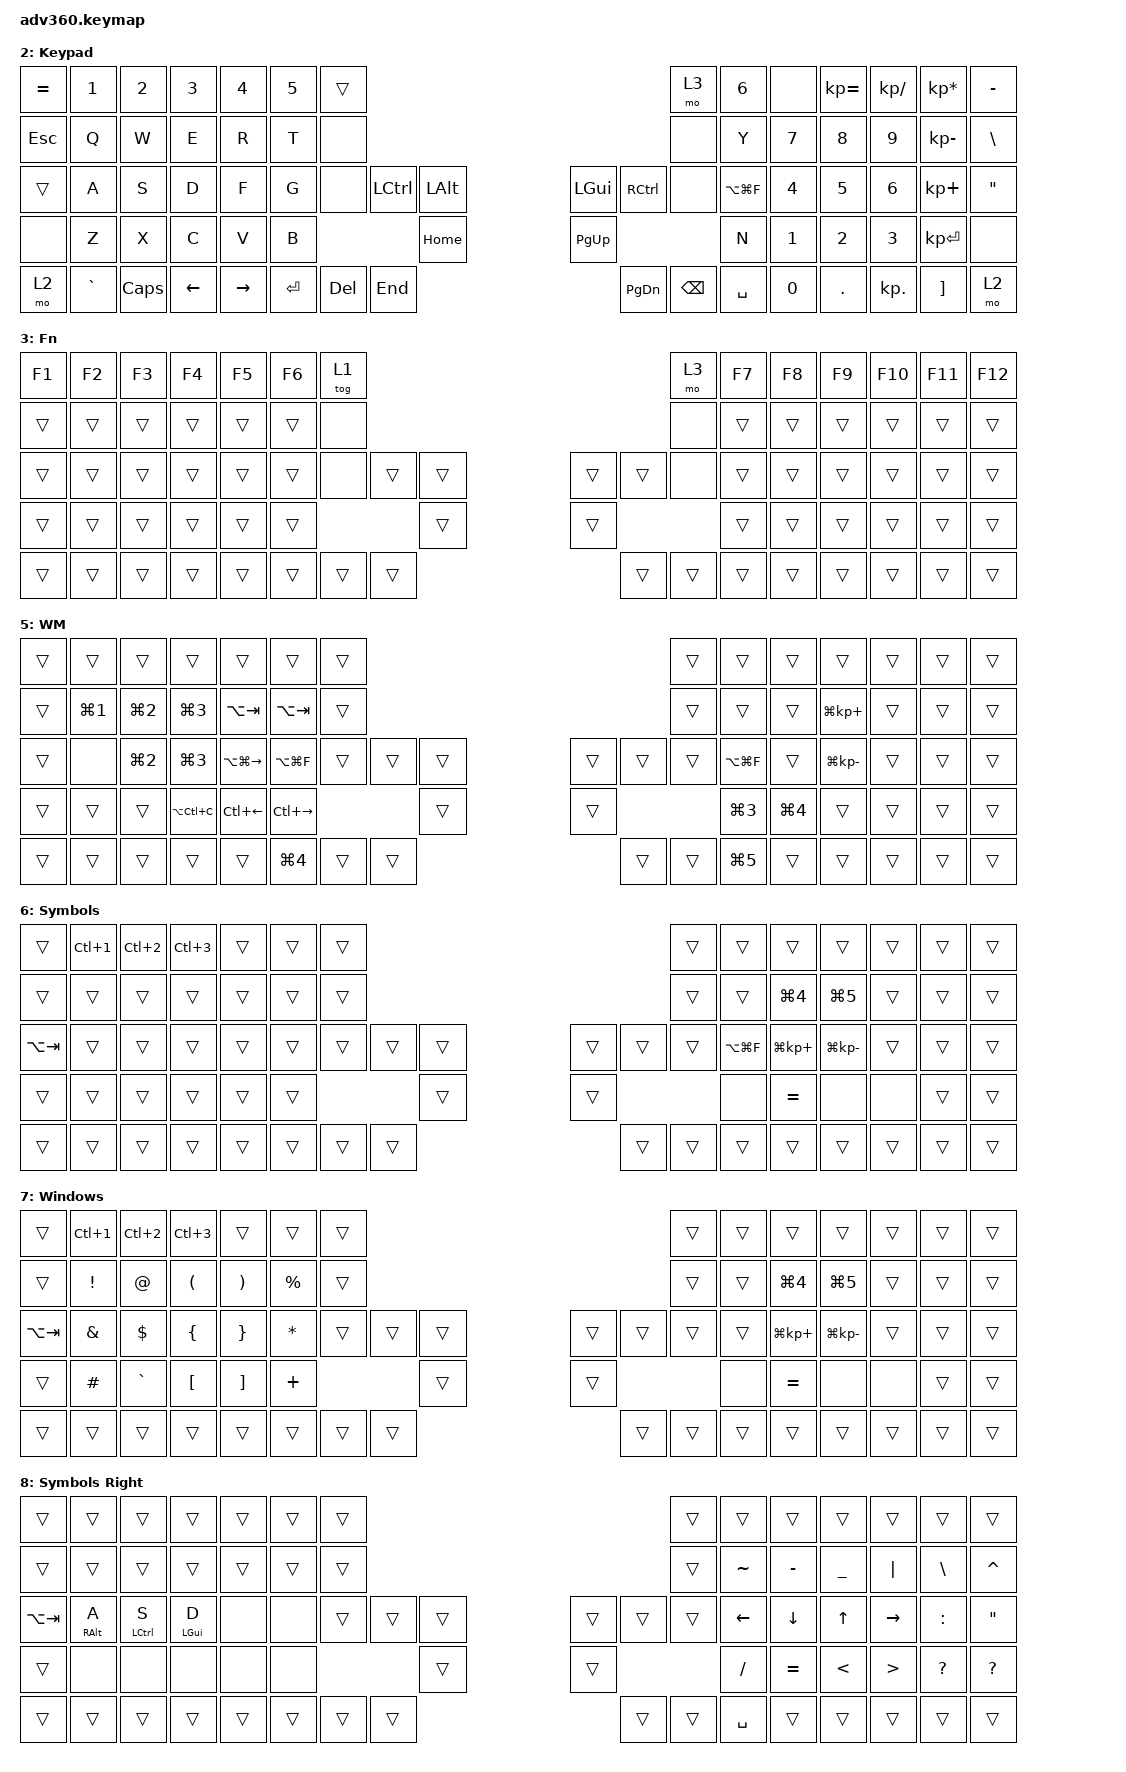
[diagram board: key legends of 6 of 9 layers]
#include <behaviors.dtsi>
#include <dt-bindings/zmk/keys.h>
#include <dt-bindings/zmk/bt.h>
#include <dt-bindings/zmk/rgb.h>
#include <dt-bindings/zmk/stp.h>
#include <dt-bindings/zmk/backlight.h>
#include <dt-bindings/zmk/pointing.h>

&lt {
    tapping-term-ms = <150>;
    flavor = "tap-preferred";
    quick_tap_ms = <80>;
};

&sl {
    release-after-ms = <2000>;
};

#define ZOOM_IN &kp LG(KP_PLUS)
#define ZOOM_OUT &kp LG(KP_MINUS)


/ {
    combos {
        compatible = "zmk,combos";
        combo_esc {
            timeout-ms = <50>;
            key-positions = <31 32>;
            bindings = <&kp A>;
        };
        combo_sqt {
            timeout-ms = <50>;
            key-positions = <41 42>;
            bindings = <&kp SQT>;
        };
    };

    behaviors {
      #include "macros.dtsi"
      #include "version.dtsi"
      #ifndef VERSION_MACRO
      macro_ver: macro_ver {
        compatible = "zmk,behavior-macro";
        label = "macro_version";
        #binding-cells = <0>;
        bindings = <&kp RET>;
      };
      #endif

      hm: homerow_mods {
          compatible = "zmk,behavior-hold-tap";
          label = "HOMEROW_MODS";
          #binding-cells = <2>;
          tapping-term-ms = <150>;
          quick_tap_ms = <150>;
          flavor = "tap-preferred";
          bindings = <&kp>, <&kp>;
      };

      hh: homerow_hold {
          compatible = "zmk,behavior-hold-tap";
          label = "HOMEROW_HOLD";
          #binding-cells = <2>;
          tapping-term-ms = <120>;
          quick_tap_ms = <120>;
          flavor = "balanced";
          bindings = <&mo>, <&kp>;
      };

      ht: homerow_layer_hold {
          compatible = "zmk,behavior-hold-tap";
          label = "HOMEROW_LAYER_HOLD";
          #binding-cells = <2>;
          tapping-term-ms = <150>;
          quick_tap_ms = <150>;
          flavor = "balanced";
          bindings = <&mo>, <&kp>;
      };

      hl: homerow_low_mods {
          compatible = "zmk,behavior-hold-tap";
          label = "HOMEROW_MODS";
          #binding-cells = <2>;
          tapping-term-ms = <120>;
          quick_tap_ms = <120>;
          flavor = "tap-preferred";
          bindings = <&kp>, <&kp>;
      };

      pinky: pinky_low_mod {
          compatible = "zmk,behavior-hold-tap";
          label = "HOMEROW_MODS";
          #binding-cells = <2>;
          tapping-term-ms = <210>;
          quick_tap_ms = <180>;
          flavor = "tap-preferred";
          bindings = <&kp>, <&kp>;
      };

    };

  keymap {
    compatible = "zmk,keymap";

        default_layer {
            display-name = "Base";
            bindings = <
    &kp ESC   &kp N1       &kp N2       &kp N3      &kp N4   &kp N5        &mo 4                                                                               &mo 4    &kp N6   &kp N7   &kp N8     &kp N9      &kp N0           &kp BACKSPACE
 &kp ESCAPE   &kp Q        &kp W        &kp E       &kp R    &kp T         &kp F1                                                                              &kp F2   &kp Y    &kp U    &kp I      &kp O       &kp P            &kp BACKSPACE
    &lt 2 TAB   &pinky RALT A   &hm LCTRL S  &hm LGUI D  &hh 8 F  &kp G         &kp C_VOL_DN &kp C_PP &kp PSCRN   &kp C_PREV   &kp C_NEXT     &kp C_VOL_UP              &kp H    &kp J  &hl LGUI K &hm LCTRL L &hh 7 SEMICOLON  &kp SQT
 &kp LSHIFT   &mt LSHIFT Z &kp X        &kp C       &lt 2 V    &kp B                                            &mo 4               &kp RS(LA(LG(M)))                            &kp N    &kp M    &kp COMMA   &kp DOT  &mt RIGHT_SHIFT SLASH  &mt RSHIFT SLASH
      &mo 3   &kp GRAVE    &kp CAPS     &none       &none                  &kp ENTER         &kp ESC          &kp RS(LG(SPACE))   &kp DELETE   &kp BACKSPACE  &kp SPACE        &sk RIGHT_CONTROL  &sk RGUI   &kp DOT  &kp SLASH        &tog 1
            >;
        };

        // layer 1 (colemak-dhk)
        layer_Colemak_DH {
            display-name = "Colemak DHK";
            bindings = <
    &kp ESC        &kp N1    &kp N2         &kp N3        &kp N4   &kp N5                 &none                                                                            &none            &kp N6   &kp N7   &kp N8     &kp N9   &kp N0          &kp BACKSPACE
 &kp ESCAPE        &kp Q     &kp W          &kp F         &kp P    &kp B                  &tog 1                                                                           &none            &kp J    &kp L    &kp U      &kp Y    &kp SEMICOLON   &kp BACKSPACE
    &lt 2 TAB      &pinky RALT A     &hm LCTRL R          &hh LGUI S         &hh 8 T  &kp G      &kp C_VOLUME_DOWN  &kp C_PLAY_PAUSE  &kp PRINTSCREEN       &kp C_PREV   &kp C_NEXT           &kp C_VOLUME_UP  &kp M    &ht 7 N    &hl LGUI E      &hm LCTRL I    &hh 6 O         &kp SQT
 &kp LSHIFT &mt LSHIFT Z     &kp X          &kp C         &kp D    &kp V                                                     &mo 3       &kp RS(LA(LG(M)))                                  &kp K    &kp H    &kp COMMA  &kp DOT  &mt RIGHT_SHIFT SLASH  &mt RIGHT_SHIFT SLASH
    &tog 0  &kp GRAVE  &kp CAPS  &sk RIGHT_ALT  &sk LEFT_GUI                 &kp ENTER           &kp ESC   &kp RS(LG(SPACE))          &kp DELETE   &kp BACKSPACE  &kp SPACE                 &sk RIGHT_CONTROL  &sk RGUI   &kp DOT  &kp SLASH        &tog 1
            >;
        };

        // layer 2
        layer_keypad {
            display-name = "Keypad";
            bindings = <
  &kp EQUAL     &kp N1    &kp N2    &kp N3     &kp N4  &kp N5              &trans                                                                 &mo 3  &kp N6         &none  &kp KP_EQUAL  &kp KP_DIVIDE  &kp KP_MULTIPLY          &kp MINUS
 &kp ESCAPE      &kp Q     &kp W     &kp E      &kp R   &kp T               &none                                                                 &none   &kp Y  &kp NUMBER_7  &kp NUMBER_8   &kp NUMBER_9     &kp KP_MINUS           &kp BSLH
     &trans      &kp A     &kp S     &kp D      &kp F   &kp G               &none  &kp LCTRL  &kp LALT                   &kp LGUI  &kp RCTRL      &none   &kp LA(LG(F)) &kp NUMBER_4  &kp NUMBER_5   &kp NUMBER_6      &kp KP_PLUS  &kp DOUBLE_QUOTES
      &none      &kp Z     &kp X     &kp C      &kp V   &kp B                                 &kp HOME                  &kp PG_UP                         &kp N  &kp NUMBER_1  &kp NUMBER_2   &kp NUMBER_3     &kp KP_ENTER              &none
      &mo 2  &kp GRAVE  &kp CAPS  &kp LEFT  &kp RIGHT                    &kp ENTER    &kp DEL   &kp END                  &kp PG_DN  &kp BACKSPACE  &kp SPACE   &kp NUMBER_0       &kp DOT     &kp KP_DOT         &kp RBKT              &mo 2
            >;
        };

        // layer 3
        layer_fn {
            display-name = "Fn";
            bindings = <
 &kp F1  &kp F2  &kp F3  &kp F4  &kp F5  &kp F6            &tog 1                                                   &mo 3  &kp F7  &kp F8  &kp F9  &kp F10  &kp F11  &kp F12
 &trans  &trans  &trans  &trans  &trans  &trans             &none                                                   &none  &trans  &trans  &trans   &trans   &trans   &trans
 &trans  &trans  &trans  &trans  &trans  &trans             &none  &trans  &trans                  &trans  &trans   &none  &trans  &trans  &trans   &trans   &trans   &trans
 &trans  &trans  &trans  &trans  &trans  &trans                            &trans                  &trans                  &trans  &trans  &trans   &trans   &trans   &trans
 &trans  &trans  &trans  &trans  &trans                    &trans  &trans  &trans                  &trans  &trans  &trans          &trans  &trans   &trans   &trans   &trans
            >;
        };

        // layer 4
        layer_mod {
            display-name = "Mod";
            bindings = <
  &none  &bt BT_SEL 0  &bt BT_SEL 1  &bt BT_SEL 2  &bt BT_SEL 3   &bt BT_SEL 4                  &none                                                                 &trans       &none  &none      &none       &none   &none   &none
  &none         &none         &none         &none         &none          &none            &bootloader                                                                 &bootloader  &none  &none      &none       &none   &none   &none
  &none         &none         &none         &none    &bt BT_CLR          &none                  &none  &tog 6  &tog 0    &bt BT_CLR   &none  &rgb_ug RGB_MEFS_CMD 5   &none        &none  &none      &none       &none   &none   &none
  &none         &none         &none         &none         &none  &kp RIGHT_WIN                                  &none    &none                                                     &none  &none      &none       &none   &none   &none
  &none         &none         &none         &none         &none                                 &none   &none   &none    &none       &bl BL_TOG    &rgb_ug RGB_TOG                        &bl BL_INC &bl BL_DEC  &none   &none   &none
            >;
        };

        // layer 5
        layer_WINDOW_M {
            display-name = "WM";
            bindings = <
 &trans  &trans            &trans            &trans             &trans         &trans                  &trans                                                     &trans   &trans        &trans      &trans            &trans  &trans  &trans
 &trans  &kp LG(N1)    &kp LG(N2)        &kp LG(N3)        &kp LA(TAB)    &kp LA(TAB)                  &trans                                                     &trans   &trans        &trans      &kp LG(KP_PLUS)   &trans  &trans  &trans
 &trans  &none         &kp LG(N2)        &kp LG(N3)  &kp LA(LG(RIGHT))  &kp LA(LG(F))                  &trans  &trans  &trans                  &trans  &trans     &trans   &kp LA(LG(F)) &trans      &kp LG(KP_MINUS)  &trans  &trans  &trans
 &trans  &trans            &trans     &kp LA(LC(C))       &kp LC(LEFT)  &kp LC(RIGHT)                                  &trans                  &trans                      &kp LG(N3)    &kp LG(N4)  &trans            &trans  &trans  &trans
 &trans  &trans            &trans            &trans             &trans                           &kp LG(N4)  &trans  &trans                    &trans  &trans  &kp LG(N5)			 &trans      &trans            &trans  &trans  &trans
            >;
        };

        // layer 6
        layer_symbols {
            display-name = "Symbols";
            bindings = <
            &trans       &kp LC(N1)   &kp LC(N2)        &kp LC(N3)             &trans        &trans            &trans                                                  &trans     &trans      &trans     &trans  &trans    &trans  &trans
            &trans  &trans  &trans         &trans           &trans   &trans      &trans                                                  &trans     &trans      &kp LG(N4) &kp LG(N5)   &trans    &trans  &trans
       &kp LA(TAB)         &trans   &trans    &trans    &trans  &trans      &trans  &trans  &trans               &trans  &trans     &trans &kp LA(LG(F))         &kp LG(KP_PLUS)  &kp LG(KP_MINUS)   &trans    &trans  &trans
            &trans    &trans    &trans  &trans  &trans      &trans                            &trans               &trans             &none      &kp EQUAL   &none   &none     &trans  &trans
            &trans           &trans       &trans            &trans             &trans        &trans     &trans  &trans              &trans  &trans  &trans               &trans    &trans   &trans    &trans    &trans
            >;
        };

        // layer 7
        layer_WINDOWS {
            display-name = "Windows";
            bindings = <
            &trans       &kp LC(N1)       &kp LC(N2)   &kp LC(N3)        &trans             &trans        &trans                                              &trans   &trans   &trans     &trans     &trans  &trans  &trans
            &trans       &kp EXCLAMATION  &kp AT_SIGN  &kp  LPAR         &kp RPAR           &kp PERCENT   &trans                                              &trans   &trans   &kp LG(N4) &kp LG(N5) &trans  &trans  &trans
            &kp LA(TAB)  &kp AMPERSAND    &kp DOLLAR   &kp LEFT_BRACE    &kp RIGHT_BRACE    &kp ASTERISK  &trans        &trans  &trans      &trans  &trans    &trans   &trans   ZOOM_IN    ZOOM_OUT   &trans  &trans  &trans
            &trans       &kp HASH         &kp GRAVE    &kp LEFT_BRACKET  &kp RIGHT_BRACKET  &kp PLUS                            &trans      &trans                     &none    &kp EQUAL  &none      &none   &trans  &trans
            &trans       &trans           &trans       &trans            &trans                                &trans   &trans  &trans      &trans  &trans  &trans              &trans     &trans     &trans  &trans  &trans
            >;
        };

        // layer 8
        layer_Symbols_Right {
            display-name = "Symbols Right";
            bindings = <
        &trans      &trans  &trans  &trans  &trans  &trans            &trans                                                  &trans     &trans     &trans         &trans            &trans         &trans             &trans
        &trans      &trans   &trans   &trans   &trans   &trans            &trans                                                  &trans  &kp TILDE  &kp MINUS      &kp UNDER          &kp PIPE  &kp BACKSLASH          &kp CARET
        &kp LA(TAB) &hl RALT A   &hm LCTRL S  &hm LGUI D   &none   &none            &trans  &trans  &trans                  &trans  &trans  &trans   &kp LEFT   &kp DOWN         &kp UP         &kp RIGHT      &kp COLON  &kp DOUBLE_QUOTES
        &trans      &none   &none   &none   &none   &none                            &trans                  &trans                  &kp SLASH  &kp EQUAL  &kp LESS_THAN  &kp GREATER_THAN   &kp QUESTION             &kp QUESTION
        &trans      &trans  &trans  &trans  &trans                    &trans  &trans  &trans                  &trans  &trans  &kp SPACE                &trans         &trans            &trans         &trans             &trans
            >;
        };

        extra1 {
          display-name = "Red";
          status = "reserved";
        };

        extra2 {
          display-name = "Purple";
          status = "reserved";
        };

        extra3 {
          display-name = "Cyan";
          status = "reserved";
        };

        extra4 {
          display-name = "Yellow";
          status = "reserved";
        };
  };
};


//        layer_Colemak_DH {
//            bindings = <
//    &kp ESC        &kp N1    &kp N2         &kp N3        &kp N4   &kp N5                 &none                                                                            &none            &kp N6   &kp N7   &kp N8     &kp N9   &kp N0          &kp BACKSPACE
// &kp ESCAPE        &kp Q     &kp W          &kp F         &kp P    &kp B                  &tog 1                                                                             &none          &kp J    &kp L    &kp U      &kp Y    &kp SEMICOLON   &kp BACKSPACE
//    &lt 2 TAB      &kp A     &kp R          &kp S         &hh 8 T    &kp G      &kp C_VOLUME_DOWN  &kp C_PLAY_PAUSE  &kp PRINTSCREEN       &kp C_PREV   &kp C_NEXT            &kp C_VOLUME_UP &kp M    &kp N    &kp E      &kp I    &hh 6 O           &kp SQT
// &kp LSHIFT &mt LSHIFT Z     &kp X          &kp C         &kp D    &kp V                                                     &mo 3       &kp RS(LA(LG(M)))                                  &kp K    &kp H    &kp COMMA  &kp DOT  &mt RIGHT_SHIFT SLASH  &mt RIGHT_SHIFT SLASH
//    &tog 0  &kp GRAVE  &kp CAPS  &sk RIGHT_ALT  &sk LEFT_GUI                 &kp ENTER           &kp ESC   &kp RS(LG(SPACE))          &kp DELETE   &kp BACKSPACE  &kp SPACE                 &sk RIGHT_CONTROL  &sk RGUI   &kp DOT  &kp SLASH        &none
//            >;
//        };

//        layer_workman {
//            bindings = <
//    &kp ESC        &kp N1    &kp N2         &kp N3        &kp N4   &kp N5                 &none                                                                            &none            &kp N6   &kp N7   &kp N8     &kp N9   &kp N0          &kp BACKSPACE
// &kp ESCAPE        &kp Q     &kp D          &kp R         &kp W    &kp B                  &tog 1                                                                           &none            &kp J    &kp F    &kp U      &kp P    &kp SEMICOLON   &kp BACKSPACE
//    &lt 2 TAB      &kp A     &kp S          &kp H         &hh 8 T  &kp G      &kp C_VOLUME_DOWN  &kp C_PLAY_PAUSE  &kp PRINTSCREEN       &kp C_PREV   &kp C_NEXT           &kp C_VOLUME_UP  &kp Y    &kp N    &kp E      &kp O    &hh 6 I         &kp SQT
// &kp LSHIFT &mt LSHIFT Z     &kp X          &kp M         &kp C    &kp V                                                     &mo 3       &kp RS(LA(LG(M)))                                  &kp K    &kp L    &kp COMMA  &kp DOT  &mt RIGHT_SHIFT SLASH  &mt RIGHT_SHIFT SLASH
//    &tog 0  &kp GRAVE  &kp CAPS  &sk RIGHT_ALT  &sk LEFT_GUI                 &kp ENTER           &kp ESC   &kp RS(LG(SPACE))          &kp DELETE   &kp BACKSPACE  &kp SPACE                 &sk RIGHT_CONTROL  &sk RGUI   &kp DOT  &kp SLASH        &none
//            >;
//        };

